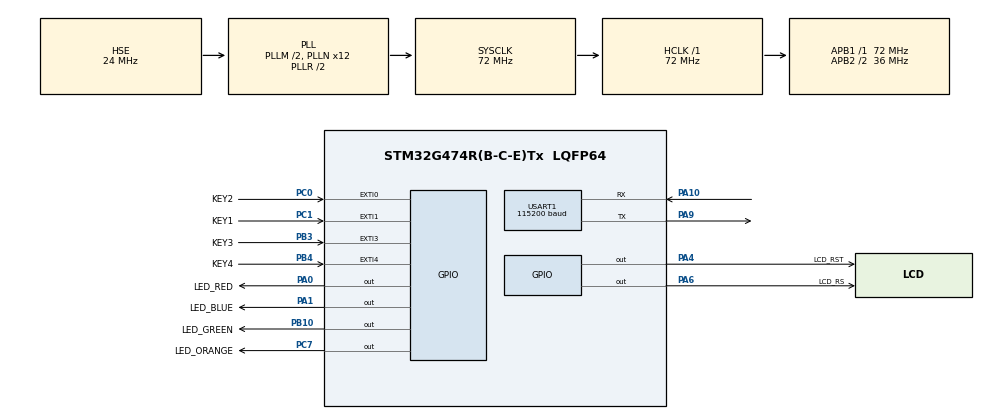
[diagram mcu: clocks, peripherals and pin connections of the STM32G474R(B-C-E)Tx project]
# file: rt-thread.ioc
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Mcu.Family=STM32G4
Mcu.Name=STM32G474R(B-C-E)Tx
Mcu.Package=LQFP64
NVIC.EXTI0_IRQn=true\:15\:0\:true\:false\:true\:false\:true\:true\:true
NVIC.EXTI1_IRQn=true\:15\:0\:true\:false\:true\:false\:true\:true\:true
NVIC.EXTI3_IRQn=true\:15\:0\:true\:false\:true\:false\:true\:true\:true
NVIC.EXTI4_IRQn=true\:15\:0\:true\:false\:true\:false\:true\:true\:true
NVIC.PriorityGroup=NVIC_PRIORITYGROUP_4
PA0.GPIO_Label=LED_RED
PA0.GPIO_PuPd=GPIO_NOPULL
PA0.PinState=GPIO_PIN_RESET
PA0.Signal=GPIO_Output
PA1.GPIO_Label=LED_BLUE
PA1.Signal=GPIO_Output
PA10.Mode=Asynchronous
PA10.Signal=USART1_RX
PA13.Mode=Serial_Wire
PA13.Signal=SYS_JTMS-SWDIO
PA14.Mode=Serial_Wire
PA14.Signal=SYS_JTCK-SWCLK
PA4.GPIO_Label=LCD_RST
PA4.GPIO_PuPd=GPIO_NOPULL
PA4.GPIO_Speed=GPIO_SPEED_FREQ_LOW
PA4.PinState=GPIO_PIN_SET
PA4.Signal=GPIO_Output
PA6.GPIO_Label=LCD_RS
PA6.GPIO_Speed=GPIO_SPEED_FREQ_VERY_HIGH
PA6.PinState=GPIO_PIN_RESET
PA6.Signal=GPIO_Output
PA9.Mode=Asynchronous
PA9.Signal=USART1_TX
PB10.GPIO_Label=LED_GREEN
PB10.PinState=GPIO_PIN_RESET
PB10.Signal=GPIO_Output
PB3.GPIO_Label=KEY3
PB3.Signal=GPXTI3
PB4.GPIO_Label=KEY4
PB4.Signal=GPXTI4
PC0.GPIO_Label=KEY2
PC0.GPIO_ModeDefaultEXTI=GPIO_MODE_IT_FALLING
PC0.Signal=GPXTI0
PC1.GPIO_Label=KEY1
PC1.GPIO_ModeDefaultEXTI=GPIO_MODE_IT_FALLING
PC1.Signal=GPXTI1
PC14-OSC32_IN.Mode=LSE-External-Oscillator
PC14-OSC32_IN.Signal=RCC_OSC32_IN
PC15-OSC32_OUT.Mode=LSE-External-Oscillator
PC15-OSC32_OUT.Signal=RCC_OSC32_OUT
PC7.GPIO_Label=LED_ORANGE
PC7.PinState=GPIO_PIN_SET
PC7.Signal=GPIO_Output
PF0-OSC_IN.Mode=HSE-External-Oscillator
PF0-OSC_IN.Signal=RCC_OSC_IN
PF1-OSC_OUT.Mode=HSE-External-Oscillator
PF1-OSC_OUT.Signal=RCC_OSC_OUT
ProjectManager.HeapSize=0x200
ProjectManager.StackSize=0x400
ProjectManager.TargetToolchain=MDK-ARM V5.32
RCC.ADC12Freq_Value=72000000
RCC.ADC345Freq_Value=72000000
RCC.AHBFreq_Value=72000000
RCC.APB1Freq_Value=72000000
RCC.APB1TimFreq_Value=72000000
RCC.APB2CLKDivider=RCC_HCLK_DIV2
RCC.APB2Freq_Value=36000000
RCC.APB2TimFreq_Value=72000000
RCC.CortexFreq_Value=72000000
RCC.EXTERNAL_CLOCK_VALUE=12288000
RCC.HCLKFreq_Value=72000000
RCC.HSE_VALUE=24000000
RCC.HSI48_VALUE=48000000
RCC.HSI_VALUE=16000000
RCC.PLLM=RCC_PLLM_DIV2
RCC.PLLN=12
RCC.PLLSourceVirtual=RCC_PLLSOURCE_HSE
RCC.RTCClockSelection=RCC_RTCCLKSOURCE_LSE
RCC.SYSCLKFreq_VALUE=72000000
RCC.SYSCLKSource=RCC_SYSCLKSOURCE_PLLCLK
RCC.USBFreq_Value=72000000
RCC.VCOOutputFreq_Value=144000000
RealThread.RT-Thread.3.1.5.RTOSJjdevice=true
RealThread.RT-Thread.3.1.5.RTOSJjkernel=true
RealThread.RT-Thread.3.1.5.RTOSJjshell=true
RealThread.RT-Thread.3.1.5.RT_USING_SEMAPHORE=0
USART1.BaudRate=115200
USART1.VirtualMode-Asynchronous=VM_ASYNC
VP_RealThread.RT-Thread_VS_RTOSJjdevice_3.1.5_3.1.5.Mode=RTOSJjdevice
VP_RealThread.RT-Thread_VS_RTOSJjkernel_3.1.5_3.1.5.Mode=RTOSJjkernel
VP_RealThread.RT-Thread_VS_RTOSJjshell_3.1.5_3.1.5.Mode=RTOSJjshell
VP_SYS_VS_DBSignals.Mode=DisableDeadBatterySignals
board=custom

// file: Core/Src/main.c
/* USER CODE BEGIN Header */
/**
  ******************************************************************************
  * @file           : main.c
  * @brief          : Main program body
  ******************************************************************************
  * @attention
  *
  * Copyright (c) 2022 STMicroelectronics.
  * All rights reserved.
  *
  * This software is licensed under terms that can be found in the LICENSE file
  * in the root directory of this software component.
  * If no LICENSE file comes with this software, it is provided AS-IS.
  *
  ******************************************************************************
  */
/* USER CODE END Header */
#include "main.h"
#include "usart.h"
#include "gpio.h"

/* USER CODE BEGIN Includes */
#include "rtthread.h"
/* USER CODE END Includes */

void SystemClock_Config(void);

/* USER CODE BEGIN 0 */
void led_task(void *arg)
{
  while (1) {
    rt_thread_mdelay(500);
//    rt_kprintf("hello\n");
    HAL_GPIO_TogglePin(LED_ORANGE_GPIO_Port, LED_ORANGE_Pin);
  }
}
/* USER CODE END 0 */

int main(void)
{

  /* MCU Configuration--------------------------------------------------------*/

  /* Reset of all peripherals, Initializes the Flash interface and the Systick. */
  HAL_Init();

  /* Configure the system clock */
  SystemClock_Config();

  /* Initialize all configured peripherals */
  MX_GPIO_Init();
  MX_USART1_UART_Init();
  /* USER CODE BEGIN 2 */
  struct rt_thread led_tid;
  static rt_uint8_t led_stack[512];

  rt_err_t result;

  result = rt_thread_init(&led_tid, "tled", led_task, RT_NULL,
                        led_stack, sizeof(led_stack), 6, 20);
  RT_ASSERT(result == RT_EOK);

  (void)result;
//  tid_led = rt_thread_create("thread_led", led_task, RT_NULL, 256, 5, 20);

  rt_thread_startup(&led_tid);
  /* USER CODE END 2 */

  /* Infinite loop */
  /* USER CODE BEGIN WHILE */
  while (1)
  {
    rt_thread_mdelay(1000);
    /* USER CODE END WHILE */

  }
}

void SystemClock_Config(void)
{
  RCC_OscInitTypeDef RCC_OscInitStruct = {0};
  RCC_ClkInitTypeDef RCC_ClkInitStruct = {0};

  /** Configure the main internal regulator output voltage
  */
  HAL_PWREx_ControlVoltageScaling(PWR_REGULATOR_VOLTAGE_SCALE1);

  /** Initializes the RCC Oscillators according to the specified parameters
  * in the RCC_OscInitTypeDef structure.
  */
  RCC_OscInitStruct.OscillatorType = RCC_OSCILLATORTYPE_HSE;
  RCC_OscInitStruct.HSEState = RCC_HSE_ON;
  RCC_OscInitStruct.PLL.PLLState = RCC_PLL_ON;
  RCC_OscInitStruct.PLL.PLLSource = RCC_PLLSOURCE_HSE;
  RCC_OscInitStruct.PLL.PLLM = RCC_PLLM_DIV2;
  RCC_OscInitStruct.PLL.PLLN = 12;
  RCC_OscInitStruct.PLL.PLLP = RCC_PLLP_DIV2;
  RCC_OscInitStruct.PLL.PLLQ = RCC_PLLQ_DIV2;
  RCC_OscInitStruct.PLL.PLLR = RCC_PLLR_DIV2;
  if (HAL_RCC_OscConfig(&RCC_OscInitStruct) != HAL_OK)
  {
    Error_Handler();
  }

  /** Initializes the CPU, AHB and APB buses clocks
  */
  RCC_ClkInitStruct.ClockType = RCC_CLOCKTYPE_HCLK|RCC_CLOCKTYPE_SYSCLK
                              |RCC_CLOCKTYPE_PCLK1|RCC_CLOCKTYPE_PCLK2;
  RCC_ClkInitStruct.SYSCLKSource = RCC_SYSCLKSOURCE_PLLCLK;
  RCC_ClkInitStruct.AHBCLKDivider = RCC_SYSCLK_DIV1;
  RCC_ClkInitStruct.APB1CLKDivider = RCC_HCLK_DIV1;
  RCC_ClkInitStruct.APB2CLKDivider = RCC_HCLK_DIV2;

  if (HAL_RCC_ClockConfig(&RCC_ClkInitStruct, FLASH_LATENCY_2) != HAL_OK)
  {
    Error_Handler();
  }
}

void Error_Handler(void)
{
  __disable_irq();
  while (1)
  {
  }
}
